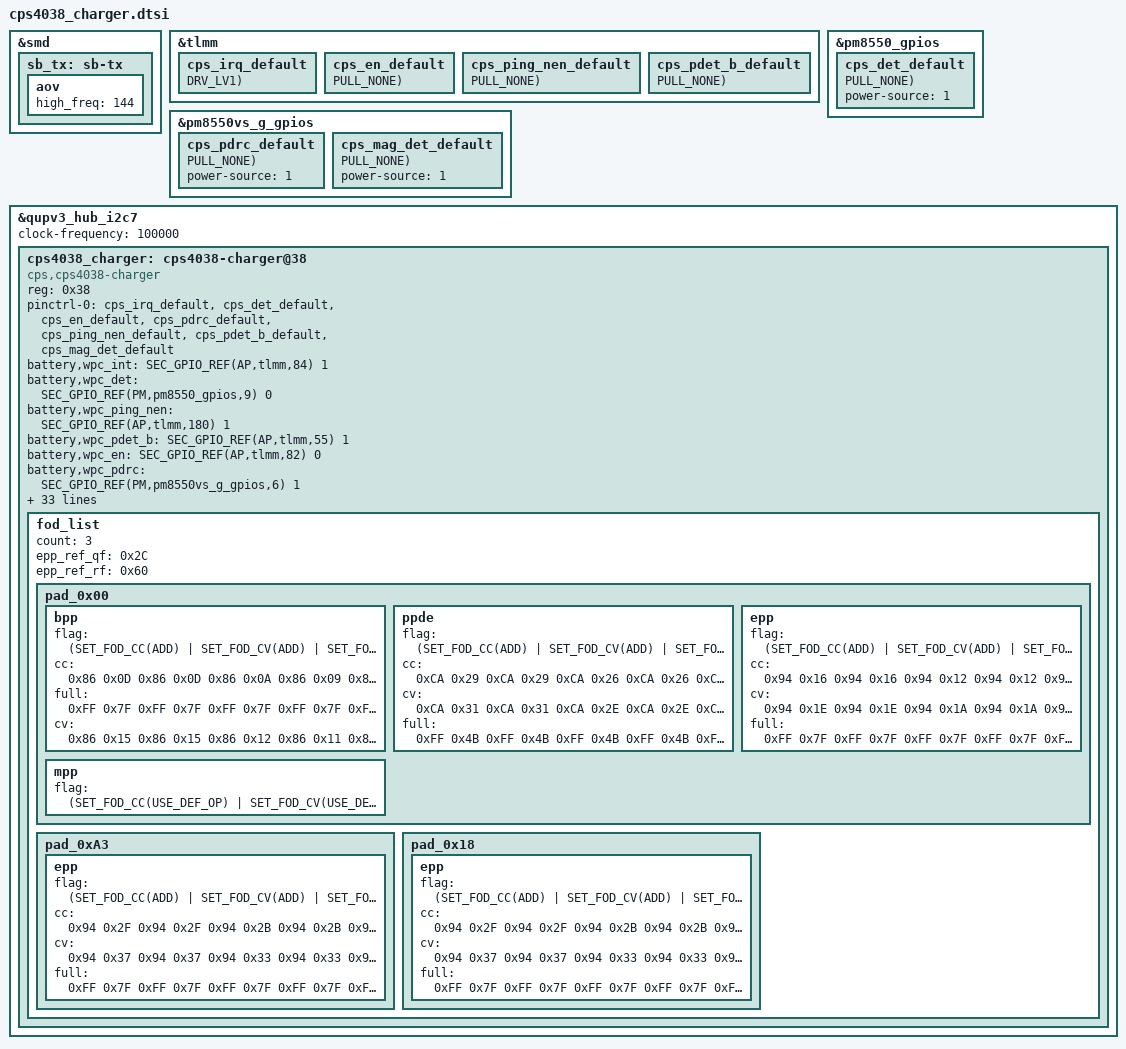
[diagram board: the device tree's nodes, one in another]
#include <dt-bindings/battery/sec-battery.h>

&smd {
	sb_tx: sb-tx {
	       aov {
		       high_freq = <144>;
	       };
       };
};

&tlmm {
	cps_irq_default: cps_irq_default {
		GPIO_CONFIG_PUD_DRV(AP,tlmm,84, FUNC_INPUT_WAKEUP, PULL_NONE, DRV_LV1);
	};
};

&pm8550_gpios {
	cps_det_default: cps_det_default {
		GPIO_CONFIG_PUD(PM,pm8550_gpios,9, FUNC_INPUT_WAKEUP, PULL_NONE);
	};
};

&tlmm {
	cps_en_default: cps_en_default {
		GPIO_CONFIG_PUD(AP,tlmm,82, FUNC_OUTPUT_LOW, PULL_NONE);
	};
};

#if 1
&pm8550vs_g_gpios {
	cps_pdrc_default: cps_pdrc_default {
		GPIO_CONFIG_PUD(PM,pm8550vs_g_gpios,6, FUNC_INPUT_WAKEUP, PULL_NONE);
	};
};
#endif

#if 1
&tlmm {
	cps_ping_nen_default: cps_ping_nen_default {
		GPIO_CONFIG_PUD(AP,tlmm,180, FUNC_OUTPUT_HIGH, PULL_NONE);
	};
};
#endif

#if 1
&tlmm {
	cps_pdet_b_default: cps_pdet_b_default {
		GPIO_CONFIG_PUD(AP,tlmm,55, FUNC_INPUT_WAKEUP, PULL_NONE);
	};
};
#endif

#if 1
&pm8550vs_g_gpios {
	cps_mag_det_default: cps_mag_det_default {
		GPIO_CONFIG_PUD(PM,pm8550vs_g_gpios,5, FUNC_OUTPUT_HIGH, PULL_NONE);
	};
};
#endif

&qupv3_hub_i2c7 {
	#address-cells = <1>;
	#size-cells = <0>;
	status = "okay";
	clock-frequency = <100000>;

	cps4038_charger: cps4038-charger@38 {
		compatible = "cps,cps4038-charger";
		reg = <0x38>;
		status = "okay";

		pinctrl-names = "default";
		pinctrl-0 = <&cps_irq_default &cps_det_default &cps_en_default
#if 1
			&cps_pdrc_default
#endif
#if 1
			&cps_ping_nen_default
#endif
#if 1
			&cps_pdet_b_default
#endif
#if 1
			&cps_mag_det_default
#endif
			>;

		battery,wpc_int = <SEC_GPIO_REF(AP,tlmm,84) 1>; /* MFC_AP_INT */
		battery,wpc_det = <SEC_GPIO_REF(PM,pm8550_gpios,9) 0>; /* WPC_DET */
#if 0
		battery,mst_pwr_en = <SEC_GPIO_REF(${cps_pwr_en_gpio}) 0>; /* MST_PWR_EN */
#endif
#if 1
		battery,wpc_ping_nen = <SEC_GPIO_REF(AP,tlmm,180) 1>; /* PING_NEN */
#endif
#if 1
		battery,wpc_pdet_b = <SEC_GPIO_REF(AP,tlmm,55) 1>; /* PDET_B */
#endif
		battery,wpc_en = <SEC_GPIO_REF(AP,tlmm,82) 0>; /* WPC_EN */
#if 1
		battery,wpc_pdrc = <SEC_GPIO_REF(PM,pm8550vs_g_gpios,6) 1>; /* VRECT_INT */
#endif
#if 1
		battery,wpc_mag_det = <SEC_GPIO_REF(PM,pm8550vs_g_gpios,5) 0>; /* MAG_DET */
#endif

		battery,charger_name = "max77775-charger";
		battery,fuelgauge_name = "max77775-fuelgauge";
		battery,wireless_charger_name = "cps4038-charger";
		battery,wc_cover_rpp = <0x44>;
		battery,phone_fod_threshold = <0x3b>;
		battery,wireless20_vout_list = <WIRELESS_VOUT_9V /* 0xA0 */
						WIRELESS_VOUT_12V /* 0xA1 */
						WIRELESS_VOUT_12V /* 0xA2 */
						WIRELESS_VOUT_12V /* 0xA3 */
						WIRELESS_VOUT_12V /* 0xA4 */
						WIRELESS_VOUT_12V>; /* 0xA5 */
		battery,wireless20_vrect_list = <MFC_AFC_CONF_12V_TX
						MFC_AFC_CONF_12_5V_TX
						MFC_AFC_CONF_12_5V_TX
						MFC_AFC_CONF_12_5V_TX
						MFC_AFC_CONF_12_5V_TX
						MFC_AFC_CONF_12_5V_TX>;
		battery,wireless20_max_power_list = <SEC_WIRELESS_RX_POWER_12W
						SEC_WIRELESS_RX_POWER_15W
						SEC_WIRELESS_RX_POWER_15W
						SEC_WIRELESS_RX_POWER_15W
						SEC_WIRELESS_RX_POWER_15W
						SEC_WIRELESS_RX_POWER_15W>;

		battery,buds_fod_ta_thresh = <0x0898>; /* 2200mW */
		battery,wpc_vout_ctrl_full = <WIRELESS_VOUT_5V_STEP>;
		battery,mis_align_guide;
		battery,mis_align_target_vout = <5000>;
		battery,mpp_epp_vout = <WIRELESS_VOUT_12V>;

		fod_list {
			count = <1>;

			pad_0x00 { /* DEFAULT PAD */
				bpp { /* DEFAULT OP MODE */
					flag = <(SET_FOD_CC(ADD) | SET_FOD_CV(USE_CC) | SET_FOD_FULL(ADD))>;
					cc = <0x4E 0x0F 0x4E 0x10 0x4E 0x0C 0x4E 0x0C 0x4E 0x0C 0x4E 0x0C 0x4E 0x0D 0x4E 0x0D 0x4E 0x0D 0x4E 0x0D>;
					full = <0xFF 0x7F 0xFF 0x7F 0xFF 0x7F 0xFF 0x7F 0xFF 0x7F
						0xFF 0x7F 0xFF 0x7F 0xFF 0x7F 0xFF 0x7F 0xFF 0x7F>;
				};

				ppde {
					flag = <(SET_FOD_CC(USE_DEF_OP) | SET_FOD_CV(USE_DEF_OP) | SET_FOD_FULL(USE_DEF_OP))>;
				};

				epp {
					flag = <(SET_FOD_CC(USE_DEF_OP) | SET_FOD_CV(USE_DEF_OP) | SET_FOD_FULL(USE_DEF_OP))>;
				};

				mpp {
					flag = <(SET_FOD_CC(USE_DEF_OP) | SET_FOD_CV(USE_DEF_OP) | SET_FOD_FULL(USE_DEF_OP))>;
				};
			};
		};
	};
};

/* /home/dpi/qb5_8814/workspace/P4_1716/android/kernel_platform/kmodule/battery/suwon/wireless/cps4038/cps4038_charger.b6q.dtsi */
#include <dt-bindings/battery/sec-battery.h>

&cps_pdrc_default {
	power-source = <1>; /* need to set default MV gpio to LV */
};

&cps_det_default {
	power-source = <1>; /* need to set default MV gpio to LV */
};

#if 1
&cps_mag_det_default {
	power-source = <1>; /* need to set default MV gpio to LV */
};
#endif

&cps4038_charger {
	battery,mst_iset_pcr = <0x06>;  //2.8A
	battery,unknown_cmb_ctrl;
	battery,default_clamp_volt;
	battery,gear_op_freq = <0x0596>; /* 143kHZ */
	battery,tx_gear_min_op_freq_delay = <4000>;
	battery,gear_min_op_freq = <1300>;

	battery,tx_max_op_freq = <1450>;
	battery,tx_min_op_freq = <1120>;
	battery,wireless20_iec_ploss_fod_enable = <0x1>;
	battery,tx_fod_gain = <0x76>;
	battery,tx_fod_offset = <0064>;
	battery,phone_fod_thresh1 = <0x0898>;
	battery,buds_fod_thresh1 = <0x0898>;
	battery,phone_fod_ta_thresh = <0x03E8>;
	battery,buds_fod_ta_thresh = <0x0898>;

	fod_list {
		epp_ref_qf = <0x2C>;
		epp_ref_rf = <0x60>;

		count = <3>;

		pad_0x00 { /* DEFAULT */
			bpp { /* DEFAULT OP MODE */
				flag = <(SET_FOD_CC(ADD) | SET_FOD_CV(ADD) | SET_FOD_FULL(ADD))>;
				cc = <0x86 0x0D 0x86 0x0D 0x86 0x0A 0x86 0x09 0x86 0x09 0x86 0x09 0x86 0x0A 0x86 0x0A 0x86 0x0A 0x86 0x0A>;
				cv = <0x86 0x15 0x86 0x15 0x86 0x12 0x86 0x11 0x86 0x11 0x86 0x11 0x86 0x12 0x86 0x12 0x86 0x12 0x86 0x12>;
				full = <0xFF 0x7F 0xFF 0x7F 0xFF 0x7F 0xFF 0x7F 0xFF 0x7F 0xFF 0x7F 0xFF 0x7F 0xFF 0x7F 0xFF 0x7F 0xFF 0x7F>;
			};

			epp {
				flag = <(SET_FOD_CC(ADD) | SET_FOD_CV(ADD) | SET_FOD_FULL(ADD))>;
				cc = <0x94 0x16 0x94 0x16 0x94 0x12 0x94 0x12 0x94 0x15 0x94 0x16 0x94 0x18 0x94 0x18 0x94 0x18 0x0C 0x01>;
				cv = <0x94 0x1E 0x94 0x1E 0x94 0x1A 0x94 0x1A 0x94 0x1D 0x94 0x1E 0x94 0x20 0x94 0x20 0x94 0x20 0x0C 0x01>;
				full = <0xFF 0x7F 0xFF 0x7F 0xFF 0x7F 0xFF 0x7F 0xFF 0x7F 0xFF 0x7F 0xFF 0x7F 0xFF 0x7F 0xFF 0x7F 0xFF 0x7F>;
			};

			ppde {
				flag = <(SET_FOD_CC(ADD) | SET_FOD_CV(ADD) | SET_FOD_FULL(ADD))>;
				cc = <0xCA 0x29 0xCA 0x29 0xCA 0x26 0xCA 0x26 0xCA 0x26 0xCA 0x26 0xCA 0x26 0xCA 0x26 0xCA 0x26 0xCA 0x26>;
				cv = <0xCA 0x31 0xCA 0x31 0xCA 0x2E 0xCA 0x2E 0xCA 0x2E 0xCA 0x2E 0xCA 0x2E 0xCA 0x2E 0xCA 0x2E 0xCA 0x2E>;
				full = <0xFF 0x4B 0xFF 0x4B 0xFF 0x4B 0xFF 0x4B 0xFF 0x4B 0xFF 0x4B 0xFF 0x4B 0xFF 0x4B 0xFF 0x4B 0xFF 0x4B>;
			};
		};

		pad_0xA3 { /* p2400 */
			epp {
				flag = <(SET_FOD_CC(ADD) | SET_FOD_CV(ADD) | SET_FOD_FULL(ADD))>;
				cc = <0x94 0x2F 0x94 0x2F 0x94 0x2B 0x94 0x2B 0x94 0x2E 0x94 0x2F 0x94 0x31 0x94 0x31 0x94 0x31 0x0C 0x01>;
				cv = <0x94 0x37 0x94 0x37 0x94 0x33 0x94 0x33 0x94 0x36 0x94 0x37 0x94 0x39 0x94 0x39 0x94 0x39 0x0C 0x01>;
				full = <0xFF 0x7F 0xFF 0x7F 0xFF 0x7F 0xFF 0x7F 0xFF 0x7F 0xFF 0x7F 0xFF 0x7F 0xFF 0x7F 0xFF 0x7F 0xFF 0x7F>;
			};
		};
		
		pad_0x18 { /* p2400 */
			epp {
				flag = <(SET_FOD_CC(ADD) | SET_FOD_CV(ADD) | SET_FOD_FULL(ADD))>;
				cc = <0x94 0x2F 0x94 0x2F 0x94 0x2B 0x94 0x2B 0x94 0x2E 0x94 0x2F 0x94 0x31 0x94 0x31 0x94 0x31 0x0C 0x01>;
				cv = <0x94 0x37 0x94 0x37 0x94 0x33 0x94 0x33 0x94 0x36 0x94 0x37 0x94 0x39 0x94 0x39 0x94 0x39 0x0C 0x01>;
				full = <0xFF 0x7F 0xFF 0x7F 0xFF 0x7F 0xFF 0x7F 0xFF 0x7F 0xFF 0x7F 0xFF 0x7F 0xFF 0x7F 0xFF 0x7F 0xFF 0x7F>;
			};
		};
	};
};
